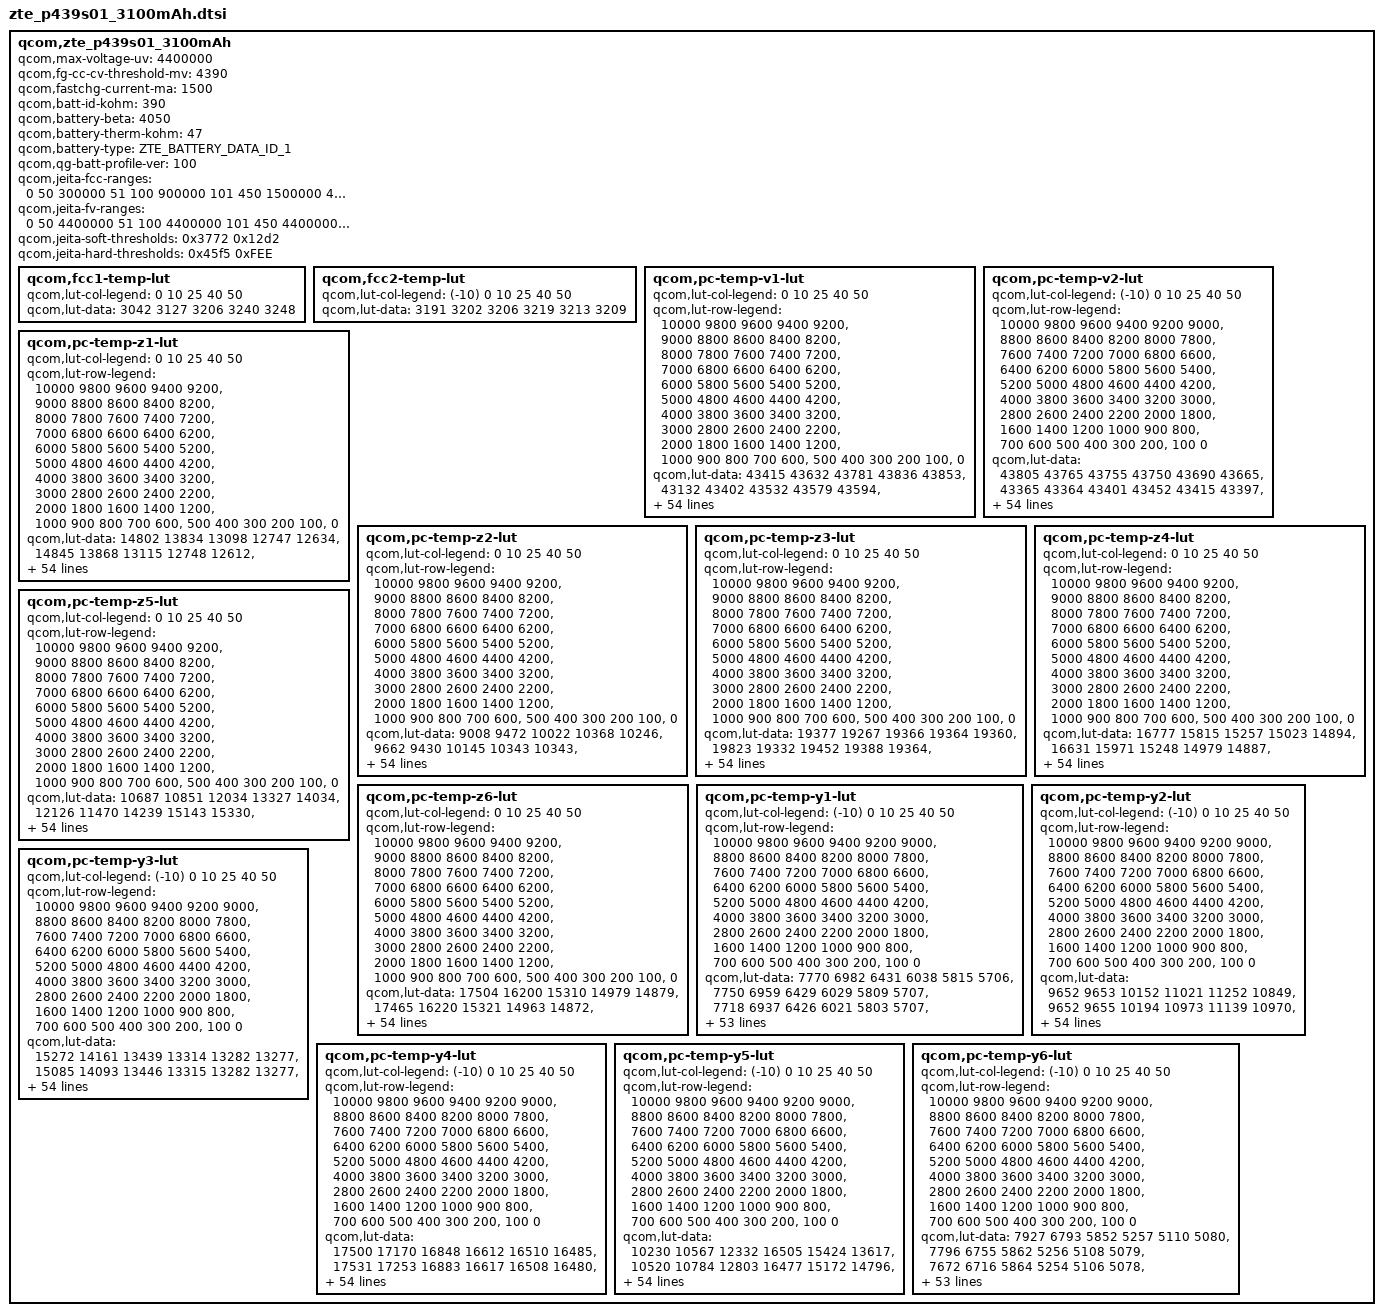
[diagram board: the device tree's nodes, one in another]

qcom,zte_p439s01_3100mAh {
	/* 3682354_Zebra_P439S01_3100mAh_averaged_MasterSlave_Sep26th2018 */
	qcom,max-voltage-uv = <4400000>;
	qcom,fg-cc-cv-threshold-mv = <4390>;
	qcom,fastchg-current-ma = <1500>;
	qcom,batt-id-kohm = <390>;
	qcom,battery-beta = <4050>;
	qcom,battery-therm-kohm = <47>;
	qcom,battery-type = "ZTE_BATTERY_DATA_ID_1";
	qcom,qg-batt-profile-ver = <100>;

	qcom,jeita-fcc-ranges = <0   50   300000
				 51 100  900000
				 101 450  1500000
				 451 500  1000000>;
	qcom,jeita-fv-ranges =  <0   50  4400000
				 51 100  4400000
				 101 450  4400000
				 451 500  4100000>;

	/* COOL = 10 DegC, WARM = 45 DegC */
	qcom,jeita-soft-thresholds = <0x3772 0x12d2>;
	/* COLD = 0 DegC, HOT = 50 DegC */
	qcom,jeita-hard-thresholds = <0x45f5 0xFEE>;

	qcom,fcc1-temp-lut {
		qcom,lut-col-legend = <0 10 25 40 50>;
		qcom,lut-data = <3042 3127 3206 3240 3248>;
	};

	qcom,fcc2-temp-lut {
		qcom,lut-col-legend = <(-10) 0 10 25 40 50>;
		qcom,lut-data = <3191 3202 3206 3219 3213 3209>;
	};

	qcom,pc-temp-v1-lut {
		qcom,lut-col-legend = <0 10 25 40 50>;
		qcom,lut-row-legend = <10000 9800 9600 9400 9200>,
			<9000 8800 8600 8400 8200>,
			<8000 7800 7600 7400 7200>,
			<7000 6800 6600 6400 6200>,
			<6000 5800 5600 5400 5200>,
			<5000 4800 4600 4400 4200>,
			<4000 3800 3600 3400 3200>,
			<3000 2800 2600 2400 2200>,
			<2000 1800 1600 1400 1200>,
			<1000 900 800 700 600>,
			<500 400 300 200 100>,
			<0>;
		qcom,lut-data = <43415 43632 43781 43836 43853>,
			<43132 43402 43532 43579 43594>,
			<42872 43136 43283 43341 43359>,
			<42631 42874 43042 43105 43125>,
			<42406 42635 42804 42867 42890>,
			<42197 42403 42565 42629 42655>,
			<42001 42174 42329 42394 42421>,
			<41800 41947 42096 42160 42187>,
			<41593 41728 41866 41928 41957>,
			<41387 41516 41640 41699 41729>,
			<41192 41310 41418 41473 41503>,
			<41004 41116 41202 41253 41279>,
			<40802 40934 40997 41038 41061>,
			<40569 40739 40803 40829 40852>,
			<40336 40509 40607 40626 40648>,
			<40143 40283 40401 40429 40451>,
			<39972 40108 40205 40239 40258>,
			<39822 39962 40037 40061 40077>,
			<39696 39820 39884 39894 39905>,
			<39583 39685 39732 39731 39739>,
			<39464 39546 39584 39574 39580>,
			<39344 39386 39415 39411 39419>,
			<39223 39208 39161 39203 39224>,
			<39100 39026 38892 38957 38986>,
			<38977 38814 38753 38780 38796>,
			<38849 38639 38673 38667 38669>,
			<38709 38558 38599 38571 38562>,
			<38590 38506 38525 38472 38459>,
			<38507 38459 38453 38379 38364>,
			<38440 38416 38383 38298 38278>,
			<38396 38375 38315 38227 38203>,
			<38367 38335 38258 38165 38134>,
			<38342 38296 38209 38113 38076>,
			<38314 38258 38165 38065 38022>,
			<38280 38223 38124 38017 37969>,
			<38244 38188 38086 37970 37918>,
			<38207 38155 38044 37919 37861>,
			<38163 38121 38002 37866 37797>,
			<38102 38068 37947 37803 37725>,
			<38020 37968 37856 37721 37640>,
			<37920 37847 37740 37618 37542>,
			<37790 37718 37613 37499 37426>,
			<37642 37574 37468 37355 37288>,
			<37479 37410 37300 37193 37131>,
			<37322 37265 37148 37044 36983>,
			<37219 37165 37059 36959 36901>,
			<37182 37131 37035 36938 36878>,
			<37153 37104 37021 36921 36863>,
			<37126 37079 37002 36904 36847>,
			<37076 37033 36951 36844 36781>,
			<36845 36792 36698 36573 36501>,
			<36388 36342 36251 36119 36036>,
			<35797 35750 35660 35527 35434>,
			<34990 34939 34848 34714 34618>,
			<33706 33666 33574 33438 33344>,
			<30000 30000 30000 30000 30000>;
	};

	qcom,pc-temp-v2-lut {
		qcom,lut-col-legend = <(-10) 0 10 25 40 50>;
		qcom,lut-row-legend = <10000 9800 9600 9400 9200 9000>,
			<8800 8600 8400 8200 8000 7800>,
			<7600 7400 7200 7000 6800 6600>,
			<6400 6200 6000 5800 5600 5400>,
			<5200 5000 4800 4600 4400 4200>,
			<4000 3800 3600 3400 3200 3000>,
			<2800 2600 2400 2200 2000 1800>,
			<1600 1400 1200 1000 900 800>,
			<700 600 500 400 300 200>,
			<100 0>;
		qcom,lut-data = <43805 43765 43755 43750 43690 43665>,
			<43365 43364 43401 43452 43415 43397>,
			<42970 42998 43077 43172 43151 43139>,
			<42623 42671 42789 42911 42902 42893>,
			<42316 42379 42532 42668 42666 42659>,
			<42035 42104 42282 42429 42432 42426>,
			<41763 41839 42035 42193 42199 42193>,
			<41523 41592 41794 41959 41968 41962>,
			<41342 41368 41550 41730 41740 41734>,
			<41197 41161 41308 41503 41514 41509>,
			<41009 40968 41097 41281 41293 41287>,
			<40720 40793 40922 41064 41077 41070>,
			<40415 40604 40740 40853 40865 40858>,
			<40150 40348 40497 40653 40660 40654>,
			<39892 40060 40228 40457 40460 40454>,
			<39663 39845 40028 40261 40269 40262>,
			<39459 39686 39877 40063 40086 40076>,
			<39265 39514 39722 39881 39909 39898>,
			<39072 39284 39545 39726 39746 39734>,
			<38891 39042 39355 39568 39580 39570>,
			<38745 38835 39142 39371 39392 39381>,
			<38621 38647 38903 39146 39184 39173>,
			<38512 38500 38697 38937 38984 38976>,
			<38418 38386 38522 38738 38783 38782>,
			<38335 38293 38373 38568 38609 38612>,
			<38261 38218 38256 38439 38480 38485>,
			<38195 38155 38159 38333 38375 38380>,
			<38132 38099 38084 38236 38278 38282>,
			<38072 38048 38024 38148 38190 38192>,
			<38013 38000 37972 38068 38109 38109>,
			<37955 37952 37925 37996 38035 38034>,
			<37897 37904 37882 37928 37966 37963>,
			<37841 37856 37840 37866 37905 37901>,
			<37783 37807 37802 37807 37849 37845>,
			<37725 37757 37760 37756 37785 37777>,
			<37664 37707 37712 37714 37703 37674>,
			<37600 37652 37658 37670 37615 37562>,
			<37530 37589 37598 37609 37529 37467>,
			<37454 37515 37530 37535 37442 37378>,
			<37373 37435 37450 37456 37362 37293>,
			<37284 37346 37348 37370 37290 37215>,
			<37195 37243 37232 37263 37191 37118>,
			<37111 37120 37099 37131 37060 36991>,
			<37028 36976 36964 36985 36928 36851>,
			<36943 36849 36822 36852 36801 36751>,
			<36853 36764 36719 36802 36775 36730>,
			<36807 36731 36685 36782 36765 36715>,
			<36751 36695 36645 36759 36743 36699>,
			<36678 36651 36592 36721 36706 36656>,
			<36549 36561 36498 36621 36584 36484>,
			<36305 36327 36276 36317 36233 36067>,
			<35900 35866 35826 35806 35703 35522>,
			<35313 35223 35183 35132 35015 34792>,
			<34460 34297 34289 34185 34056 33758>,
			<33027 32812 32845 32693 32575 32260>,
			<29458 27461 27293 27285 27144 27098>;
	};

	qcom,pc-temp-z1-lut {
		qcom,lut-col-legend = <0 10 25 40 50>;
		qcom,lut-row-legend = <10000 9800 9600 9400 9200>,
			<9000 8800 8600 8400 8200>,
			<8000 7800 7600 7400 7200>,
			<7000 6800 6600 6400 6200>,
			<6000 5800 5600 5400 5200>,
			<5000 4800 4600 4400 4200>,
			<4000 3800 3600 3400 3200>,
			<3000 2800 2600 2400 2200>,
			<2000 1800 1600 1400 1200>,
			<1000 900 800 700 600>,
			<500 400 300 200 100>,
			<0>;
		qcom,lut-data = <14802 13834 13098 12747 12634>,
			<14845 13868 13115 12748 12612>,
			<14831 13850 13074 12722 12584>,
			<14775 13823 13054 12707 12576>,
			<14725 13789 13036 12693 12566>,
			<14700 13750 13016 12681 12558>,
			<14676 13714 12993 12666 12553>,
			<14648 13673 12978 12658 12550>,
			<14608 13655 12967 12659 12549>,
			<14569 13658 12962 12662 12549>,
			<14546 13661 12970 12661 12550>,
			<14525 13653 12980 12660 12551>,
			<14498 13621 12979 12660 12552>,
			<14438 13600 12974 12659 12553>,
			<14376 13592 12970 12660 12554>,
			<14359 13585 12970 12659 12555>,
			<14352 13582 12970 12658 12557>,
			<14351 13579 12974 12659 12559>,
			<14357 13580 12982 12663 12561>,
			<14367 13596 12986 12667 12563>,
			<14373 13613 12985 12668 12566>,
			<14381 13613 12985 12669 12568>,
			<14384 13602 12981 12670 12570>,
			<14377 13599 12975 12670 12572>,
			<14363 13607 12977 12672 12574>,
			<14361 13616 12992 12677 12578>,
			<14367 13619 13004 12682 12584>,
			<14373 13619 13009 12686 12589>,
			<14380 13619 13013 12691 12595>,
			<14395 13619 13017 12695 12600>,
			<14400 13621 13022 12702 12606>,
			<14402 13633 13028 12708 12612>,
			<14404 13652 13038 12711 12618>,
			<14397 13658 13045 12713 12623>,
			<14379 13652 13046 12720 12629>,
			<14376 13647 13045 12731 12634>,
			<14419 13654 13047 12739 12639>,
			<14469 13672 13053 12745 12645>,
			<14489 13682 13061 12750 12651>,
			<14503 13689 13074 12756 12656>,
			<14513 13692 13088 12763 12661>,
			<14520 13690 13097 12770 12666>,
			<14528 13689 13103 12776 12671>,
			<14538 13700 13114 12778 12675>,
			<14577 13720 13125 12778 12681>,
			<14533 13751 13124 12788 12685>,
			<14561 13748 13129 12796 12687>,
			<14588 13735 13133 12801 12691>,
			<14583 13718 13131 12805 12695>,
			<14611 13734 13145 12809 12699>,
			<14623 13789 13154 12818 12709>,
			<14635 13804 13169 12834 12720>,
			<14660 13839 13182 12845 12735>,
			<14743 13874 13198 12866 12758>,
			<14743 13874 13198 12866 12758>,
			<14743 13874 13198 12866 12758>;
	};

	qcom,pc-temp-z2-lut {
		qcom,lut-col-legend = <0 10 25 40 50>;
		qcom,lut-row-legend = <10000 9800 9600 9400 9200>,
			<9000 8800 8600 8400 8200>,
			<8000 7800 7600 7400 7200>,
			<7000 6800 6600 6400 6200>,
			<6000 5800 5600 5400 5200>,
			<5000 4800 4600 4400 4200>,
			<4000 3800 3600 3400 3200>,
			<3000 2800 2600 2400 2200>,
			<2000 1800 1600 1400 1200>,
			<1000 900 800 700 600>,
			<500 400 300 200 100>,
			<0>;
		qcom,lut-data = <9008 9472 10022 10368 10246>,
			<9662 9430 10145 10343 10343>,
			<9850 9776 10273 10422 10324>,
			<9862 9981 10269 10427 10384>,
			<9866 9975 10262 10407 10412>,
			<9702 9964 10238 10381 10407>,
			<9319 9952 10197 10336 10365>,
			<9185 9939 10173 10308 10320>,
			<9291 9928 10157 10302 10294>,
			<9418 9918 10150 10299 10273>,
			<9473 9911 10167 10300 10263>,
			<9513 9916 10192 10302 10257>,
			<9536 9936 10201 10304 10252>,
			<9592 9947 10208 10295 10246>,
			<9650 9948 10215 10284 10243>,
			<9686 9949 10226 10284 10253>,
			<9791 9955 10236 10288 10279>,
			<9848 9972 10245 10305 10286>,
			<9729 9985 10253 10348 10286>,
			<9564 9992 10257 10374 10286>,
			<9533 9998 10259 10372 10294>,
			<9532 10002 10259 10364 10313>,
			<9532 10006 10250 10343 10338>,
			<9564 10006 10238 10292 10383>,
			<9616 9989 10237 10279 10415>,
			<9644 9973 10241 10354 10432>,
			<9745 9977 10249 10425 10435>,
			<9823 9991 10291 10430 10406>,
			<9825 9998 10334 10415 10349>,
			<9824 9999 10325 10391 10309>,
			<9817 9999 10291 10339 10271>,
			<9748 10002 10269 10312 10243>,
			<9684 10008 10256 10333 10230>,
			<9643 10010 10249 10365 10222>,
			<9568 10006 10263 10382 10232>,
			<9548 10003 10292 10395 10278>,
			<9633 10005 10307 10420 10340>,
			<9718 10009 10314 10482 10460>,
			<9714 10015 10324 10529 10546>,
			<9675 10026 10361 10539 10534>,
			<9626 10033 10401 10546 10505>,
			<9549 10027 10398 10547 10485>,
			<9492 10017 10380 10546 10458>,
			<9451 9891 10384 10542 10459>,
			<9407 9848 10420 10536 10476>,
			<9356 9746 10452 10516 10487>,
			<9350 9942 10325 10509 10497>,
			<9346 9933 10358 10515 10486>,
			<9328 10080 10353 10573 10585>,
			<9315 10287 10382 10636 10664>,
			<9284 10225 10481 10552 10434>,
			<9255 9830 10494 10447 10290>,
			<9212 9624 10478 10369 10233>,
			<9168 9554 10408 10347 10207>,
			<9168 9554 10408 10347 10207>,
			<9168 9554 10408 10347 10207>;
	};

	qcom,pc-temp-z3-lut {
		qcom,lut-col-legend = <0 10 25 40 50>;
		qcom,lut-row-legend = <10000 9800 9600 9400 9200>,
			<9000 8800 8600 8400 8200>,
			<8000 7800 7600 7400 7200>,
			<7000 6800 6600 6400 6200>,
			<6000 5800 5600 5400 5200>,
			<5000 4800 4600 4400 4200>,
			<4000 3800 3600 3400 3200>,
			<3000 2800 2600 2400 2200>,
			<2000 1800 1600 1400 1200>,
			<1000 900 800 700 600>,
			<500 400 300 200 100>,
			<0>;
		qcom,lut-data = <19377 19267 19366 19364 19360>,
			<19823 19332 19452 19388 19364>,
			<19979 19581 19523 19412 19371>,
			<20016 19734 19539 19437 19402>,
			<20031 19747 19545 19448 19409>,
			<19858 19754 19548 19450 19414>,
			<19449 19754 19550 19450 19417>,
			<19287 19750 19550 19450 19419>,
			<19276 19745 19547 19446 19414>,
			<19270 19727 19541 19439 19402>,
			<19269 19699 19530 19430 19395>,
			<19268 19671 19515 19419 19391>,
			<19274 19639 19499 19410 19386>,
			<19421 19627 19482 19403 19377>,
			<19589 19642 19475 19398 19369>,
			<19657 19660 19474 19395 19367>,
			<19837 19651 19474 19392 19366>,
			<19918 19615 19471 19389 19364>,
			<19662 19598 19465 19384 19361>,
			<19329 19598 19463 19381 19357>,
			<19272 19597 19461 19382 19355>,
			<19271 19610 19462 19383 19353>,
			<19272 19647 19467 19382 19352>,
			<19369 19665 19473 19379 19350>,
			<19527 19668 19471 19377 19351>,
			<19597 19668 19456 19375 19364>,
			<19777 19665 19449 19375 19380>,
			<19914 19660 19462 19399 19395>,
			<19912 19653 19482 19440 19411>,
			<19901 19646 19496 19448 19415>,
			<19870 19639 19508 19441 19407>,
			<19703 19636 19511 19432 19397>,
			<19549 19634 19502 19420 19387>,
			<19463 19633 19490 19408 19377>,
			<19318 19630 19483 19399 19369>,
			<19269 19624 19477 19391 19361>,
			<19267 19610 19472 19389 19359>,
			<19265 19589 19468 19389 19361>,
			<19265 19584 19464 19389 19362>,
			<19265 19593 19460 19384 19361>,
			<19266 19600 19457 19377 19360>,
			<19268 19592 19453 19376 19358>,
			<19269 19573 19449 19376 19355>,
			<19270 19464 19446 19376 19357>,
			<19272 19350 19437 19372 19358>,
			<19274 19267 19408 19355 19340>,
			<19274 19264 19396 19347 19338>,
			<19274 19264 19355 19347 19333>,
			<19275 19262 19331 19341 19322>,
			<19276 19261 19336 19334 19319>,
			<19278 19261 19326 19348 19348>,
			<19281 19264 19321 19359 19359>,
			<19287 19268 19313 19362 19361>,
			<19295 19269 19313 19362 19364>,
			<19295 19269 19313 19362 19364>,
			<19295 19269 19313 19362 19364>;
	};

	qcom,pc-temp-z4-lut {
		qcom,lut-col-legend = <0 10 25 40 50>;
		qcom,lut-row-legend = <10000 9800 9600 9400 9200>,
			<9000 8800 8600 8400 8200>,
			<8000 7800 7600 7400 7200>,
			<7000 6800 6600 6400 6200>,
			<6000 5800 5600 5400 5200>,
			<5000 4800 4600 4400 4200>,
			<4000 3800 3600 3400 3200>,
			<3000 2800 2600 2400 2200>,
			<2000 1800 1600 1400 1200>,
			<1000 900 800 700 600>,
			<500 400 300 200 100>,
			<0>;
		qcom,lut-data = <16777 15815 15257 15023 14894>,
			<16631 15971 15248 14979 14887>,
			<16430 15766 15405 15007 14872>,
			<16107 15553 15279 15027 14936>,
			<15882 15389 15130 14955 14892>,
			<15950 15243 15043 14903 14852>,
			<16129 15136 14973 14866 14820>,
			<16191 15050 14917 14836 14794>,
			<16125 14992 14868 14808 14779>,
			<16031 14958 14833 14785 14768>,
			<15960 14931 14811 14774 14757>,
			<15895 14907 14794 14767 14748>,
			<15814 14885 14781 14759 14740>,
			<15611 14863 14771 14748 14733>,
			<15406 14833 14762 14737 14726>,
			<15294 14810 14756 14726 14716>,
			<15045 14809 14750 14716 14703>,
			<14913 14814 14737 14706 14693>,
			<15158 14815 14722 14696 14684>,
			<15495 14802 14718 14691 14680>,
			<15551 14787 14720 14693 14682>,
			<15536 14784 14726 14699 14688>,
			<15517 14788 14815 14743 14720>,
			<15399 14802 14949 14859 14820>,
			<15225 14882 14968 14901 14865>,
			<15160 14960 14958 14892 14844>,
			<14990 14953 14942 14876 14811>,
			<14859 14920 14904 14834 14778>,
			<14856 14890 14858 14772 14741>,
			<14857 14866 14823 14748 14722>,
			<14875 14843 14793 14738 14713>,
			<15028 14821 14777 14730 14707>,
			<15166 14799 14770 14722 14701>,
			<15242 14785 14765 14717 14697>,
			<15387 14773 14759 14718 14698>,
			<15430 14767 14754 14721 14703>,
			<15418 14768 14751 14724 14708>,
			<15404 14772 14748 14728 14716>,
			<15392 14773 14747 14731 14721>,
			<15379 14768 14753 14735 14721>,
			<15369 14765 14760 14738 14720>,
			<15363 14768 14756 14735 14717>,
			<15354 14774 14744 14724 14710>,
			<15329 14881 14742 14725 14711>,
			<15226 14960 14735 14725 14714>,
			<15171 14990 14707 14699 14692>,
			<15166 14982 14705 14690 14678>,
			<15163 14974 14731 14665 14661>,
			<15155 14968 14744 14651 14648>,
			<15142 14962 14740 14663 14656>,
			<15134 14972 14775 14679 14655>,
			<15157 14981 14787 14674 14652>,
			<15175 14989 14800 14673 14653>,
			<15198 15003 14806 14675 14653>,
			<15198 15003 14806 14675 14653>,
			<15198 15003 14806 14675 14653>;
	};

	qcom,pc-temp-z5-lut {
		qcom,lut-col-legend = <0 10 25 40 50>;
		qcom,lut-row-legend = <10000 9800 9600 9400 9200>,
			<9000 8800 8600 8400 8200>,
			<8000 7800 7600 7400 7200>,
			<7000 6800 6600 6400 6200>,
			<6000 5800 5600 5400 5200>,
			<5000 4800 4600 4400 4200>,
			<4000 3800 3600 3400 3200>,
			<3000 2800 2600 2400 2200>,
			<2000 1800 1600 1400 1200>,
			<1000 900 800 700 600>,
			<500 400 300 200 100>,
			<0>;
		qcom,lut-data = <10687 10851 12034 13327 14034>,
			<12126 11470 14239 15143 15330>,
			<12860 13024 14686 15763 16092>,
			<13259 14285 15193 15694 16328>,
			<13453 14852 15810 16413 16856>,
			<12815 15290 16419 16917 17393>,
			<11288 15849 17094 17238 18104>,
			<10674 16536 17880 17573 18557>,
			<10627 16833 18869 18178 18466>,
			<10599 16616 19626 18774 18287>,
			<10570 16241 20163 18764 18338>,
			<10545 15905 20542 18450 18720>,
			<10587 15542 20457 18291 18909>,
			<11983 15461 20048 18495 18604>,
			<13585 18022 19917 18867 18285>,
			<14285 21015 20939 19524 18677>,
			<16199 20545 22440 20552 20118>,
			<17003 18109 23700 21365 21346>,
			<14408 17045 24981 22216 22441>,
			<11116 17412 26072 23207 23186>,
			<10550 18236 27463 24799 23510>,
			<10556 22158 28547 26206 23701>,
			<10570 31349 29232 25451 22966>,
			<12002 35808 29798 22200 19608>,
			<14760 35775 28411 19359 17418>,
			<17786 34569 22258 16840 16660>,
			<25700 32300 19184 15399 16250>,
			<31350 28698 19568 17340 17397>,
			<30850 26130 20357 21598 20565>,
			<29165 24262 22659 24505 22771>,
			<26614 23211 27470 26765 24318>,
			<20860 23422 30364 28168 25327>,
			<15773 24070 31827 28900 25995>,
			<13589 24605 32726 29385 26484>,
			<11335 25490 33411 29735 26490>,
			<10654 25932 34058 30033 26476>,
			<10635 24171 33960 30076 26506>,
			<10625 21070 32812 29585 26488>,
			<10627 20504 31326 28730 26299>,
			<10637 22879 29267 25949 25064>,
			<10646 24768 27071 22200 22857>,
			<10653 23215 25797 21406 21486>,
			<10659 20417 24897 21317 20603>,
			<10663 16684 23917 20504 20071>,
			<10779 13603 23013 19495 19405>,
			<10784 11115 21321 18889 17826>,
			<10765 11061 19397 18212 18262>,
			<10750 11027 14927 20148 19420>,
			<10749 11007 13346 20879 19443>,
			<10784 11040 13655 18100 17405>,
			<10871 11108 12974 17227 21003>,
			<10833 11079 12554 17602 22181>,
			<10793 11039 12188 17874 20975>,
			<10740 10972 12040 17319 21021>,
			<10740 10972 12040 17319 21021>,
			<10740 10972 12040 17319 21021>;
	};

	qcom,pc-temp-z6-lut {
		qcom,lut-col-legend = <0 10 25 40 50>;
		qcom,lut-row-legend = <10000 9800 9600 9400 9200>,
			<9000 8800 8600 8400 8200>,
			<8000 7800 7600 7400 7200>,
			<7000 6800 6600 6400 6200>,
			<6000 5800 5600 5400 5200>,
			<5000 4800 4600 4400 4200>,
			<4000 3800 3600 3400 3200>,
			<3000 2800 2600 2400 2200>,
			<2000 1800 1600 1400 1200>,
			<1000 900 800 700 600>,
			<500 400 300 200 100>,
			<0>;
		qcom,lut-data = <17504 16200 15310 14979 14879>,
			<17465 16220 15321 14963 14872>,
			<17376 16149 15400 14980 14864>,
			<17164 16057 15333 14995 14904>,
			<16922 15941 15251 14967 14888>,
			<16735 15812 15200 14945 14873>,
			<16564 15718 15157 14927 14861>,
			<16436 15642 15120 14910 14850>,
			<16345 15579 15089 14894 14839>,
			<16268 15529 15063 14880 14828>,
			<16189 15484 15044 14869 14820>,
			<16114 15436 15028 14860 14814>,
			<16048 15387 15011 14852 14807>,
			<15992 15358 14996 14843 14800>,
			<15943 15345 14986 14835 14792>,
			<15904 15336 14982 14829 14786>,
			<15872 15326 14978 14823 14781>,
			<15843 15315 14972 14816 14776>,
			<15811 15309 14964 14810 14770>,
			<15785 15305 14962 14807 14767>,
			<15777 15304 14964 14808 14767>,
			<15774 15309 14968 14811 14769>,
			<15773 15330 15010 14830 14782>,
			<15775 15354 15069 14879 14825>,
			<15780 15393 15077 14896 14845>,
			<15788 15424 15066 14892 14844>,
			<15810 15420 15057 14887 14840>,
			<15826 15405 15049 14884 14836>,
			<15826 15391 15043 14880 14830>,
			<15822 15380 15038 14875 14824>,
			<15817 15370 15035 14869 14818>,
			<15801 15362 15031 14861 14811>,
			<15786 15355 15025 14852 14803>,
			<15782 15352 15021 14845 14796>,
			<15779 15351 15019 14842 14794>,
			<15779 15350 15018 14840 14792>,
			<15781 15350 15018 14840 14793>,
			<15786 15350 15019 14843 14797>,
			<15792 15352 15021 14846 14802>,
			<15801 15364 15027 14847 14802>,
			<15811 15376 15033 14847 14802>,
			<15822 15382 15034 14846 14801>,
			<15833 15386 15033 14843 14798>,
			<15844 15392 15037 14844 14799>,
			<15824 15386 15037 14845 14802>,
			<15810 15370 15018 14827 14784>,
			<15810 15368 15014 14820 14778>,
			<15811 15367 15006 14810 14768>,
			<15815 15370 15006 14802 14758>,
			<15819 15377 15012 14806 14759>,
			<15833 15391 15029 14823 14778>,
			<15857 15407 15038 14830 14786>,
			<15887 15426 15047 14836 14790>,
			<15928 15455 15060 14843 14797>,
			<15928 15455 15060 14843 14797>,
			<15928 15455 15060 14843 14797>;
	};

	qcom,pc-temp-y1-lut {
		qcom,lut-col-legend = <(-10) 0 10 25 40 50>;
		qcom,lut-row-legend = <10000 9800 9600 9400 9200 9000>,
			<8800 8600 8400 8200 8000 7800>,
			<7600 7400 7200 7000 6800 6600>,
			<6400 6200 6000 5800 5600 5400>,
			<5200 5000 4800 4600 4400 4200>,
			<4000 3800 3600 3400 3200 3000>,
			<2800 2600 2400 2200 2000 1800>,
			<1600 1400 1200 1000 900 800>,
			<700 600 500 400 300 200>,
			<100 0>;
		qcom,lut-data = <7770 6982 6431 6038 5815 5706>,
			<7750 6959 6429 6029 5809 5707>,
			<7718 6937 6426 6021 5803 5707>,
			<7685 6917 6423 6013 5797 5706>,
			<7660 6904 6421 6007 5793 5705>,
			<7652 6901 6419 6003 5792 5703>,
			<7655 6905 6414 6002 5792 5700>,
			<7659 6911 6409 6001 5793 5697>,
			<7666 6914 6406 6001 5790 5696>,
			<7679 6917 6401 6002 5784 5695>,
			<7682 6920 6400 6004 5779 5694>,
			<7673 6921 6403 6010 5775 5692>,
			<7666 6922 6408 6014 5773 5690>,
			<7677 6920 6411 6012 5772 5689>,
			<7700 6917 6415 6007 5772 5689>,
			<7705 6919 6416 6008 5772 5689>,
			<7700 6929 6412 6011 5772 5690>,
			<7697 6936 6409 6013 5772 5690>,
			<7691 6937 6417 6008 5770 5689>,
			<7682 6938 6427 6002 5769 5688>,
			<7680 6940 6427 6003 5770 5689>,
			<7680 6942 6423 6008 5773 5692>,
			<7680 6942 6420 6012 5774 5694>,
			<7676 6932 6422 6015 5774 5694>,
			<7673 6923 6424 6018 5774 5695>,
			<7682 6926 6425 6021 5775 5696>,
			<7702 6935 6427 6023 5777 5698>,
			<7708 6936 6429 6024 5780 5701>,
			<7707 6934 6432 6024 5783 5705>,
			<7705 6932 6435 6023 5786 5708>,
			<7700 6929 6434 6024 5789 5709>,
			<7693 6926 6432 6024 5791 5711>,
			<7691 6926 6434 6025 5794 5712>,
			<7695 6929 6440 6028 5799 5715>,
			<7697 6931 6443 6029 5803 5718>,
			<7699 6932 6440 6030 5805 5721>,
			<7700 6934 6437 6031 5807 5725>,
			<7699 6936 6437 6032 5809 5727>,
			<7690 6941 6436 6032 5813 5729>,
			<7686 6942 6435 6034 5815 5732>,
			<7672 6935 6429 6036 5816 5734>,
			<7665 6931 6428 6037 5820 5738>,
			<7677 6931 6433 6038 5825 5740>,
			<7704 6929 6449 6052 5827 5746>,
			<7725 6983 6459 6059 5833 5749>,
			<7723 6979 6469 6066 5836 5751>,
			<7737 6979 6456 6056 5838 5757>,
			<7743 6962 6473 6069 5838 5760>,
			<7744 6958 6462 6073 5845 5758>,
			<7776 6987 6469 6081 5843 5760>,
			<7767 6994 6471 6081 5851 5767>,
			<7805 7016 6488 6082 5864 5775>,
			<7806 7043 6511 6096 5879 5787>,
			<7868 7067 6531 6128 5895 5800>,
			<7868 7067 6531 6128 5895 5800>,
			<7868 7067 6531 6128 5895 5800>;
	};

	qcom,pc-temp-y2-lut {
		qcom,lut-col-legend = <(-10) 0 10 25 40 50>;
		qcom,lut-row-legend = <10000 9800 9600 9400 9200 9000>,
			<8800 8600 8400 8200 8000 7800>,
			<7600 7400 7200 7000 6800 6600>,
			<6400 6200 6000 5800 5600 5400>,
			<5200 5000 4800 4600 4400 4200>,
			<4000 3800 3600 3400 3200 3000>,
			<2800 2600 2400 2200 2000 1800>,
			<1600 1400 1200 1000 900 800>,
			<700 600 500 400 300 200>,
			<100 0>;
		qcom,lut-data = <9652 9653 10152 11021 11252 10849>,
			<9652 9655 10194 10973 11139 10970>,
			<9652 9657 10250 10925 11025 11035>,
			<9653 9659 10306 10881 10927 11058>,
			<9653 9660 10352 10844 10860 11052>,
			<9653 9661 10376 10817 10841 11030>,
			<9653 9663 10386 10800 10870 10952>,
			<9654 9664 10394 10786 10902 10878>,
			<9654 9664 10400 10765 10900 10872>,
			<9654 9664 10406 10742 10884 10872>,
			<9655 9664 10421 10737 10882 10871>,
			<9655 9667 10472 10745 10889 10876>,
			<9655 9668 10516 10752 10898 10881>,
			<9655 9667 10529 10761 10912 10850>,
			<9655 9665 10539 10779 10930 10794>,
			<9655 9664 10558 10801 10944 10789>,
			<9655 9664 10606 10843 10976 10826>,
			<9655 9664 10632 10891 10994 10872>,
			<9655 9663 10623 10964 11004 10931>,
			<9655 9662 10606 11020 11020 10988>,
			<9655 9662 10589 10999 11059 11025>,
			<9655 9662 10565 10933 11134 11066>,
			<9655 9662 10530 10910 11155 11075>,
			<9655 9662 10343 10912 11103 11041>,
			<9655 9661 10168 10918 11058 11010>,
			<9655 9661 10061 10929 11063 11016>,
			<9655 9660 9868 10942 11079 11036>,
			<9655 9659 9810 10957 11104 11075>,
			<9655 9658 9794 10990 11158 11171>,
			<9655 9658 9779 11011 11195 11230>,
			<9654 9657 9762 11019 11201 11233>,
			<9654 9657 9743 11023 11204 11235>,
			<9654 9656 9724 11017 11232 11254>,
			<9654 9656 9699 10998 11294 11305>,
			<9654 9655 9686 10992 11313 11329>,
			<9654 9655 9681 11008 11256 11308>,
			<9654 9654 9677 11022 11203 11288>,
			<9654 9654 9674 11008 11215 11294>,
			<9654 9654 9670 10978 11248 11297>,
			<9654 9654 9667 10960 11262 11273>,
			<9653 9653 9664 10932 11249 11220>,
			<9653 9653 9662 10893 11207 11175>,
			<9653 9653 9659 10828 11138 11145>,
			<9653 9653 9658 10779 11262 11225>,
			<9653 9653 9657 10656 11119 11096>,
			<9653 9652 9656 10645 11149 11066>,
			<9653 9652 9655 10612 11062 11056>,
			<9652 9652 9654 10614 11050 11003>,
			<9652 9652 9654 10613 11042 11019>,
			<9652 9652 9654 10563 11012 10948>,
			<9652 9652 9653 10458 10948 10916>,
			<9651 9651 9653 10380 10910 10843>,
			<9651 9651 9652 10290 10778 10754>,
			<9650 9651 9651 10183 10700 10628>,
			<9650 9651 9651 10183 10700 10628>,
			<9650 9651 9651 10183 10700 10628>;
	};

	qcom,pc-temp-y3-lut {
		qcom,lut-col-legend = <(-10) 0 10 25 40 50>;
		qcom,lut-row-legend = <10000 9800 9600 9400 9200 9000>,
			<8800 8600 8400 8200 8000 7800>,
			<7600 7400 7200 7000 6800 6600>,
			<6400 6200 6000 5800 5600 5400>,
			<5200 5000 4800 4600 4400 4200>,
			<4000 3800 3600 3400 3200 3000>,
			<2800 2600 2400 2200 2000 1800>,
			<1600 1400 1200 1000 900 800>,
			<700 600 500 400 300 200>,
			<100 0>;
		qcom,lut-data = <15272 14161 13439 13314 13282 13277>,
			<15085 14093 13446 13315 13282 13277>,
			<14907 14026 13452 13316 13283 13278>,
			<14742 13966 13457 13318 13283 13279>,
			<14592 13912 13460 13319 13284 13280>,
			<14462 13869 13461 13321 13285 13280>,
			<14338 13838 13460 13323 13285 13281>,
			<14242 13808 13458 13325 13286 13281>,
			<14193 13758 13460 13326 13286 13281>,
			<14154 13696 13464 13326 13287 13281>,
			<14134 13680 13464 13327 13288 13281>,
			<14104 13709 13457 13329 13289 13281>,
			<14073 13732 13448 13332 13291 13282>,
			<14037 13698 13439 13334 13292 13284>,
			<13984 13635 13430 13337 13293 13288>,
			<13960 13621 13424 13336 13295 13288>,
			<13949 13625 13418 13333 13299 13287>,
			<13941 13627 13412 13330 13301 13287>,
			<13932 13600 13403 13329 13302 13289>,
			<13924 13559 13393 13328 13302 13291>,
			<13926 13535 13384 13325 13301 13291>,
			<13939 13517 13375 13319 13298 13289>,
			<13952 13511 13364 13312 13294 13287>,
			<13961 13511 13340 13306 13288 13282>,
			<13972 13511 13317 13301 13284 13278>,
			<13993 13519 13299 13299 13282 13278>,
			<14025 13541 13274 13298 13281 13277>,
			<14060 13567 13270 13297 13281 13277>,
			<14096 13602 13271 13299 13282 13278>,
			<14136 13639 13273 13299 13283 13278>,
			<14179 13674 13295 13300 13283 13278>,
			<14226 13710 13326 13301 13283 13278>,
			<14275 13751 13338 13301 13283 13278>,
			<14327 13799 13345 13298 13284 13279>,
			<14382 13853 13354 13297 13285 13280>,
			<14440 13918 13364 13300 13284 13278>,
			<14500 13989 13377 13301 13283 13277>,
			<14565 14058 13400 13301 13281 13276>,
			<14635 14127 13437 13300 13278 13276>,
			<14703 14201 13478 13301 13278 13275>,
			<14764 14282 13526 13303 13282 13275>,
			<14830 14362 13581 13305 13281 13276>,
			<14908 14439 13648 13307 13278 13278>,
			<14991 14505 13734 13307 13285 13276>,
			<15025 14535 13764 13309 13279 13278>,
			<15188 14676 13902 13316 13282 13281>,
			<15289 14745 13979 13323 13288 13281>,
			<15392 14823 14070 13333 13291 13289>,
			<15518 14913 14165 13345 13297 13292>,
			<15670 15003 14252 13353 13298 13288>,
			<15852 15111 14343 13353 13295 13284>,
			<16081 15259 14453 13361 13296 13289>,
			<16440 15507 14678 13383 13301 13292>,
			<17336 15828 14969 13424 13308 13297>,
			<17336 15828 14969 13424 13308 13297>,
			<17336 15828 14969 13424 13308 13297>;
	};

	qcom,pc-temp-y4-lut {
		qcom,lut-col-legend = <(-10) 0 10 25 40 50>;
		qcom,lut-row-legend = <10000 9800 9600 9400 9200 9000>,
			<8800 8600 8400 8200 8000 7800>,
			<7600 7400 7200 7000 6800 6600>,
			<6400 6200 6000 5800 5600 5400>,
			<5200 5000 4800 4600 4400 4200>,
			<4000 3800 3600 3400 3200 3000>,
			<2800 2600 2400 2200 2000 1800>,
			<1600 1400 1200 1000 900 800>,
			<700 600 500 400 300 200>,
			<100 0>;
		qcom,lut-data = <17500 17170 16848 16612 16510 16485>,
			<17531 17253 16883 16617 16508 16480>,
			<17572 17356 16954 16621 16505 16476>,
			<17617 17454 17033 16624 16502 16473>,
			<17659 17526 17097 16626 16500 16472>,
			<17694 17548 17119 16627 16499 16471>,
			<17724 17529 17120 16626 16501 16472>,
			<17756 17510 17120 16625 16503 16474>,
			<17814 17547 17106 16626 16505 16477>,
			<17899 17650 17073 16628 16509 16481>,
			<17913 17681 17072 16631 16513 16486>,
			<17724 17640 17177 16635 16517 16491>,
			<17518 17587 17262 16640 16522 16496>,
			<17432 17497 17197 16654 16528 16500>,
			<17361 17370 17076 16676 16536 16504>,
			<17303 17325 17065 16694 16545 16511>,
			<17247 17312 17144 16710 16555 16523>,
			<17195 17294 17190 16734 16568 16537>,
			<17142 17197 17173 16795 16601 16559>,
			<17094 17056 17138 16850 16632 16576>,
			<17064 16956 17055 16832 16635 16577>,
			<17041 16871 16879 16763 16629 16573>,
			<17033 16836 16768 16693 16615 16564>,
			<17038 16827 16715 16603 16546 16517>,
			<17043 16823 16687 16545 16489 16476>,
			<17041 16823 16693 16537 16486 16474>,
			<17032 16824 16714 16533 16486 16474>,
			<17027 16823 16720 16533 16487 16474>,
			<17027 16819 16728 16536 16494 16480>,
			<17029 16816 16732 16539 16503 16487>,
			<17033 16822 16717 16543 16514 16497>,
			<17040 16834 16697 16546 16526 16511>,
			<17047 16846 16701 16546 16539 16525>,
			<17054 16861 16731 16546 16555 16540>,
			<17061 16874 16760 16546 16559 16545>,
			<17067 16885 16782 16554 16535 16515>,
			<17071 16897 16801 16561 16506 16482>,
			<17073 16909 16817 16558 16493 16476>,
			<17074 16923 16831 16554 16484 16474>,
			<17074 16931 16837 16556 16484 16475>,
			<17073 16936 16833 16571 16493 16484>,
			<17073 16938 16835 16583 16495 16484>,
			<17072 16936 16845 16594 16494 16476>,
			<17083 16917 16859 16595 16492 16476>,
			<17071 16870 16834 16573 16469 16452>,
			<17104 16898 16895 16613 16495 16475>,
			<17133 16928 16949 16651 16510 16494>,
			<17175 16970 17008 16698 16530 16523>,
			<17215 17023 17088 16755 16567 16558>,
			<17240 17083 17175 16801 16567 16536>,
			<17224 17082 17207 16759 16523 16483>,
			<17195 17021 17179 16760 16526 16495>,
			<17200 17013 17191 16812 16566 16519>,
			<17392 17054 17230 16892 16657 16630>,
			<17392 17054 17230 16892 16657 16630>,
			<17392 17054 17230 16892 16657 16630>;
	};

	qcom,pc-temp-y5-lut {
		qcom,lut-col-legend = <(-10) 0 10 25 40 50>;
		qcom,lut-row-legend = <10000 9800 9600 9400 9200 9000>,
			<8800 8600 8400 8200 8000 7800>,
			<7600 7400 7200 7000 6800 6600>,
			<6400 6200 6000 5800 5600 5400>,
			<5200 5000 4800 4600 4400 4200>,
			<4000 3800 3600 3400 3200 3000>,
			<2800 2600 2400 2200 2000 1800>,
			<1600 1400 1200 1000 900 800>,
			<700 600 500 400 300 200>,
			<100 0>;
		qcom,lut-data = <10230 10567 12332 16505 15424 13617>,
			<10520 10784 12803 16477 15172 14796>,
			<10779 10994 13333 16419 14943 15478>,
			<10986 11189 13850 16342 14738 15794>,
			<11118 11356 14284 16255 14559 15872>,
			<11155 11488 14567 16166 14406 15832>,
			<11074 11602 14760 16069 14284 15462>,
			<10982 11681 14903 15954 14179 14921>,
			<11345 11656 14908 15662 13991 14427>,
			<12437 11544 14745 15137 13655 13877>,
			<13048 11695 14679 14875 13420 13500>,
			<13415 13460 14721 14714 13457 13214>,
			<13566 14896 14779 14598 13500 13075>,
			<12919 14117 14581 14490 13363 13357>,
			<11823 12663 14201 14306 13197 13840>,
			<11567 12570 14168 13983 13219 13809>,
			<11587 13727 14365 13390 13474 13226>,
			<11600 14419 14653 13129 13614 12905>,
			<11373 13961 15349 13301 13470 12992>,
			<11012 13151 16171 13655 13300 13193>,
			<10887 12458 16598 14616 13889 13844>,
			<10818 11752 16901 16354 15647 15228>,
			<10746 11278 16918 16889 16591 15822>,
			<10618 10956 15455 16247 16716 15909>,
			<10511 10777 13843 15731 16596 15913>,
			<10536 10766 12776 15534 16060 15819>,
			<10628 10766 11299 15139 15230 15666>,
			<10673 10794 10948 15072 15089 15527>,
			<10731 10985 10906 15614 15329 15403>,
			<10778 11150 10888 15913 15510 15322>,
			<10790 11185 11168 16463 15437 15062>,
			<10822 11191 11583 17144 15311 14721>,
			<10862 11211 11704 16978 15512 14854>,
			<10931 11283 11743 16272 16146 15493>,
			<11008 11331 11751 16063 16723 15864>,
			<11093 11513 11742 16551 17255 15991>,
			<11168 11729 11737 16966 17586 16068>,
			<11185 11750 11839 16675 16868 16024>,
			<11187 11727 12087 16042 15310 15816>,
			<11176 11740 12157 15646 15080 15518>,
			<10990 11801 12072 15265 16080 14650>,
			<10876 11805 11942 15149 15717 14726>,
			<10875 11688 11771 14886 14056 15430>,
			<10833 11376 11840 14498 16650 15202>,
			<10755 11286 11662 15140 15349 17716>,
			<10818 11305 11626 14664 14215 15068>,
			<10909 11307 11654 14481 15122 14155>,
			<10979 11242 11751 14447 14611 15518>,
			<11195 11398 11921 14608 15075 15614>,
			<11340 11471 12125 14676 15753 15211>,
			<11337 11608 12222 14846 16919 16007>,
			<11162 11431 11828 15073 17112 18045>,
			<11125 11382 11356 14963 17295 18221>,
			<10829 11280 11110 14959 17415 18019>,
			<10829 11280 11110 14959 17415 18019>,
			<10829 11280 11110 14959 17415 18019>;
	};

	qcom,pc-temp-y6-lut {
		qcom,lut-col-legend = <(-10) 0 10 25 40 50>;
		qcom,lut-row-legend = <10000 9800 9600 9400 9200 9000>,
			<8800 8600 8400 8200 8000 7800>,
			<7600 7400 7200 7000 6800 6600>,
			<6400 6200 6000 5800 5600 5400>,
			<5200 5000 4800 4600 4400 4200>,
			<4000 3800 3600 3400 3200 3000>,
			<2800 2600 2400 2200 2000 1800>,
			<1600 1400 1200 1000 900 800>,
			<700 600 500 400 300 200>,
			<100 0>;
		qcom,lut-data = <7927 6793 5852 5257 5110 5080>,
			<7796 6755 5862 5256 5108 5079>,
			<7672 6716 5864 5254 5106 5078>,
			<7557 6678 5861 5252 5105 5078>,
			<7454 6640 5854 5251 5104 5078>,
			<7366 6601 5845 5250 5104 5078>,
			<7283 6560 5831 5249 5104 5079>,
			<7220 6523 5814 5248 5105 5079>,
			<7195 6496 5794 5247 5105 5080>,
			<7179 6474 5773 5245 5106 5081>,
			<7154 6463 5767 5245 5108 5082>,
			<7077 6459 5779 5246 5110 5084>,
			<6995 6451 5789 5248 5112 5086>,
			<6940 6404 5763 5251 5114 5088>,
			<6886 6332 5719 5257 5117 5091>,
			<6851 6311 5712 5261 5121 5094>,
			<6826 6307 5727 5264 5125 5097>,
			<6805 6301 5736 5268 5131 5100>,
			<6783 6264 5727 5284 5141 5108>,
			<6765 6211 5709 5298 5149 5115>,
			<6764 6177 5679 5291 5149 5114>,
			<6766 6150 5627 5266 5145 5112>,
			<6770 6141 5590 5241 5138 5107>,
			<6778 6146 5565 5211 5114 5090>,
			<6789 6155 5550 5192 5095 5076>,
			<6805 6169 5548 5189 5093 5075>,
			<6827 6192 5549 5188 5092 5075>,
			<6851 6217 5555 5188 5093 5075>,
			<6879 6246 5568 5191 5096 5077>,
			<6910 6278 5586 5194 5099 5080>,
			<6943 6312 5605 5197 5103 5083>,
			<6979 6349 5629 5200 5106 5087>,
			<7018 6391 5656 5201 5111 5092>,
			<7062 6438 5689 5201 5117 5097>,
			<7107 6489 5725 5202 5119 5099>,
			<7154 6544 5765 5207 5112 5089>,
			<7202 6603 5810 5212 5104 5079>,
			<7252 6664 5860 5213 5099 5078>,
			<7305 6728 5917 5213 5095 5077>,
			<7356 6791 5977 5216 5095 5078>,
			<7404 6853 6039 5226 5101 5080>,
			<7456 6914 6110 5237 5102 5081>,
			<7519 6974 6191 5249 5100 5080>,
			<7592 7027 6276 5257 5105 5080>,
			<7627 7048 6304 5259 5095 5075>,
			<7768 7162 6448 5290 5107 5084>,
			<7851 7227 6528 5314 5116 5091>,
			<7946 7300 6617 5344 5124 5105>,
			<8060 7384 6713 5380 5140 5117>,
			<8186 7474 6813 5412 5141 5108>,
			<8326 7558 6901 5413 5128 5091>,
			<8505 7661 6995 5443 5131 5099>,
			<8787 7852 7183 5517 5149 5110>,
			<9568 8119 7428 5623 5184 5147>,
			<9568 8119 7428 5623 5184 5147>,
			<9568 8119 7428 5623 5184 5147>;
	};
};
